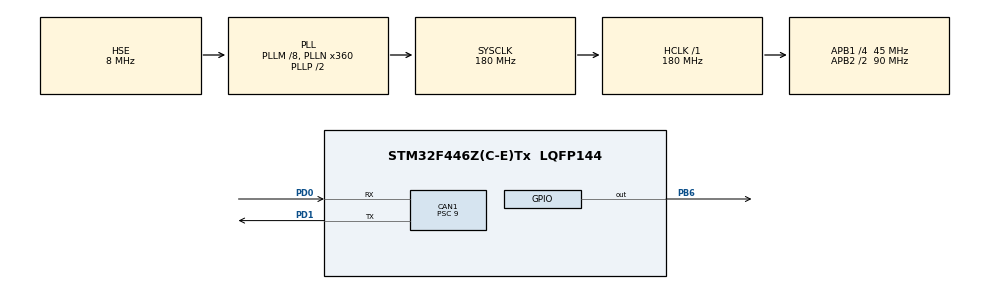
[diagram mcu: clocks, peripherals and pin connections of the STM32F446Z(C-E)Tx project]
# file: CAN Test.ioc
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CAN1.BS1=CAN_BS1_3TQ
CAN1.BS2=CAN_BS2_1TQ
CAN1.CalculateTimeBit=1000
CAN1.CalculateTimeQuantum=200.0
CAN1.Mode=CAN_MODE_NORMAL
CAN1.Prescaler=9
Mcu.Family=STM32F4
Mcu.Name=STM32F446Z(C-E)Tx
Mcu.Package=LQFP144
NVIC.PriorityGroup=NVIC_PRIORITYGROUP_4
PB6.Signal=GPIO_Output
PD0.Mode=Master
PD0.Signal=CAN1_RX
PD1.Mode=Master
PD1.Signal=CAN1_TX
PH0-OSC_IN.Mode=HSE-External-Oscillator
PH0-OSC_IN.Signal=RCC_OSC_IN
PH1-OSC_OUT.Mode=HSE-External-Oscillator
PH1-OSC_OUT.Signal=RCC_OSC_OUT
ProjectManager.HeapSize=0x200
ProjectManager.StackSize=0x400
ProjectManager.TargetToolchain=MDK-ARM V5
RCC.AHBFreq_Value=180000000
RCC.APB1CLKDivider=RCC_HCLK_DIV4
RCC.APB1Freq_Value=45000000
RCC.APB1TimFreq_Value=90000000
RCC.APB2CLKDivider=RCC_HCLK_DIV2
RCC.APB2Freq_Value=90000000
RCC.APB2TimFreq_Value=180000000
RCC.CortexFreq_Value=180000000
RCC.HCLKFreq_Value=180000000
RCC.HSE_VALUE=8000000
RCC.PLLM=8
RCC.PLLN=360
RCC.PLLSourceVirtual=RCC_PLLSOURCE_HSE
RCC.SYSCLKFreq_VALUE=180000000
RCC.SYSCLKSource=RCC_SYSCLKSOURCE_PLLCLK
RCC.USBFreq_Value=180000000
RCC.VCOOutputFreq_Value=360000000
board=CAN Test

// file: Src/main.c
/**
  ******************************************************************************
  * File Name          : main.c
  * Description        : Main program body
  ******************************************************************************
  ** This notice applies to any and all portions of this file
  * that are not between comment pairs USER CODE BEGIN and
  * USER CODE END. Other portions of this file, whether
  * inserted by the user or by software development tools
  * are owned by their respective copyright owners.
  *
  * COPYRIGHT(c) 2018 STMicroelectronics
  *
  * Redistribution and use in source and binary forms, with or without modification,
  * are permitted provided that the following conditions are met:
  *   1. Redistributions of source code must retain the above copyright notice,
  *      this list of conditions and the following disclaimer.
  *   2. Redistributions in binary form must reproduce the above copyright notice,
  *      this list of conditions and the following disclaimer in the documentation
  *      and/or other materials provided with the distribution.
  *   3. Neither the name of STMicroelectronics nor the names of its contributors
  *      may be used to endorse or promote products derived from this software
  *      without specific prior written permission.
  *
  * THIS SOFTWARE IS PROVIDED BY THE COPYRIGHT HOLDERS AND CONTRIBUTORS "AS IS"
  * AND ANY EXPRESS OR IMPLIED WARRANTIES, INCLUDING, BUT NOT LIMITED TO, THE
  * IMPLIED WARRANTIES OF MERCHANTABILITY AND FITNESS FOR A PARTICULAR PURPOSE ARE
  * DISCLAIMED. IN NO EVENT SHALL THE COPYRIGHT HOLDER OR CONTRIBUTORS BE LIABLE
  * FOR ANY DIRECT, INDIRECT, INCIDENTAL, SPECIAL, EXEMPLARY, OR CONSEQUENTIAL
  * DAMAGES (INCLUDING, BUT NOT LIMITED TO, PROCUREMENT OF SUBSTITUTE GOODS OR
  * SERVICES; LOSS OF USE, DATA, OR PROFITS; OR BUSINESS INTERRUPTION) HOWEVER
  * CAUSED AND ON ANY THEORY OF LIABILITY, WHETHER IN CONTRACT, STRICT LIABILITY,
  * OR TORT (INCLUDING NEGLIGENCE OR OTHERWISE) ARISING IN ANY WAY OUT OF THE USE
  * OF THIS SOFTWARE, EVEN IF ADVISED OF THE POSSIBILITY OF SUCH DAMAGE.
  *
  ******************************************************************************
  */

#include "main.h"
#include "stm32f4xx_hal.h"

CAN_HandleTypeDef hcan1;

/* USER CODE BEGIN PV */
/* Private variables ---------------------------------------------------------*/

/* USER CODE END PV */

void SystemClock_Config(void);
static void MX_GPIO_Init(void);
static void MX_CAN1_Init(void);

/* USER CODE BEGIN PFP */
/* Private function prototypes -----------------------------------------------*/

/* USER CODE END PFP */

int main(void)
{

  /* MCU Configuration----------------------------------------------------------*/

  /* Reset of all peripherals, Initializes the Flash interface and the Systick. */
  HAL_Init();

  /* Configure the system clock */
  SystemClock_Config();

  /* Initialize all configured peripherals */
  MX_GPIO_Init();
  MX_CAN1_Init();

  /* USER CODE BEGIN 2 */
	hcan1.pTxMsg->StdId = 0x110;
	hcan1.pTxMsg->RTR = CAN_RTR_DATA;
	hcan1.pTxMsg->IDE = CAN_ID_STD;
	hcan1.pTxMsg->DLC = 8;
  /* USER CODE END 2 */

  /* Infinite loop */
  while (1)
  {

  /* USER CODE BEGIN 3 */
		hcan1.pTxMsg->Data[0] = 1;
		hcan1.pTxMsg->Data[1] = 2;
		hcan1.pTxMsg->Data[2] = 3;
		hcan1.pTxMsg->Data[3] = 4;
		hcan1.pTxMsg->Data[4] = 0xCA;
		hcan1.pTxMsg->Data[5] = 0xFE;
		hcan1.pTxMsg->Data[6] = 0xCA;
		hcan1.pTxMsg->Data[7] = 0xFE;
		HAL_CAN_Transmit(&hcan1, 10);
		//HAL_Delay(1000);
		/*if(HAL_CAN_Receive(&hcan1,CAN_FIFO0, 10) == HAL_OK)
		{
			if(hcan1.pRxMsg->StdId  == 0x100)
			{
				if(hcan1.pRxMsg->IDE == CAN_ID_STD)
				{
					if(hcan1.pRxMsg->DLC == 2)
					{
						if(hcan1.pRxMsg->Data[0] == 0xCA)
						{
							if(hcan1.pRxMsg->Data[1] == 0xFE)
							{
								HAL_GPIO_TogglePin(GPIOB, GPIO_PIN_6);
								//HAL_Delay(100);
							}
						}
					}
				}
			}
		}*/
  }
  /* USER CODE END 3 */

}

/** System Clock Configuration
*/
void SystemClock_Config(void)
{

  RCC_OscInitTypeDef RCC_OscInitStruct;
  RCC_ClkInitTypeDef RCC_ClkInitStruct;

    /**Configure the main internal regulator output voltage
    */
  __HAL_RCC_PWR_CLK_ENABLE();

  __HAL_PWR_VOLTAGESCALING_CONFIG(PWR_REGULATOR_VOLTAGE_SCALE1);

    /**Initializes the CPU, AHB and APB busses clocks
    */
  RCC_OscInitStruct.OscillatorType = RCC_OSCILLATORTYPE_HSE;
  RCC_OscInitStruct.HSEState = RCC_HSE_ON;
  RCC_OscInitStruct.PLL.PLLState = RCC_PLL_ON;
  RCC_OscInitStruct.PLL.PLLSource = RCC_PLLSOURCE_HSE;
  RCC_OscInitStruct.PLL.PLLM = 8;
  RCC_OscInitStruct.PLL.PLLN = 360;
  RCC_OscInitStruct.PLL.PLLP = RCC_PLLP_DIV2;
  RCC_OscInitStruct.PLL.PLLQ = 2;
  RCC_OscInitStruct.PLL.PLLR = 2;
  if (HAL_RCC_OscConfig(&RCC_OscInitStruct) != HAL_OK)
  {
    _Error_Handler(__FILE__, __LINE__);
  }

    /**Activate the Over-Drive mode
    */
  if (HAL_PWREx_EnableOverDrive() != HAL_OK)
  {
    _Error_Handler(__FILE__, __LINE__);
  }

    /**Initializes the CPU, AHB and APB busses clocks
    */
  RCC_ClkInitStruct.ClockType = RCC_CLOCKTYPE_HCLK|RCC_CLOCKTYPE_SYSCLK
                              |RCC_CLOCKTYPE_PCLK1|RCC_CLOCKTYPE_PCLK2;
  RCC_ClkInitStruct.SYSCLKSource = RCC_SYSCLKSOURCE_PLLCLK;
  RCC_ClkInitStruct.AHBCLKDivider = RCC_SYSCLK_DIV1;
  RCC_ClkInitStruct.APB1CLKDivider = RCC_HCLK_DIV4;
  RCC_ClkInitStruct.APB2CLKDivider = RCC_HCLK_DIV2;

  if (HAL_RCC_ClockConfig(&RCC_ClkInitStruct, FLASH_LATENCY_5) != HAL_OK)
  {
    _Error_Handler(__FILE__, __LINE__);
  }

    /**Configure the Systick interrupt time
    */
  HAL_SYSTICK_Config(HAL_RCC_GetHCLKFreq()/1000);

    /**Configure the Systick
    */
  HAL_SYSTICK_CLKSourceConfig(SYSTICK_CLKSOURCE_HCLK);

  /* SysTick_IRQn interrupt configuration */
  HAL_NVIC_SetPriority(SysTick_IRQn, 0, 0);
}

/* CAN1 init function */
/* CAN1 init function */
static void MX_CAN1_Init(void)
{
	CAN_FilterConfTypeDef  sFilterConfig;
  static CanTxMsgTypeDef        TxMessage;
  static CanRxMsgTypeDef        RxMessage;

  hcan1.Instance = CAN1;
	hcan1.pTxMsg = &TxMessage;
  hcan1.pRxMsg = &RxMessage;

  hcan1.Init.Prescaler = 9;
  hcan1.Init.Mode = CAN_MODE_NORMAL;
  hcan1.Init.SJW = CAN_SJW_1TQ;
  hcan1.Init.BS1 = CAN_BS1_3TQ;
  hcan1.Init.BS2 = CAN_BS2_1TQ;
  hcan1.Init.TTCM = DISABLE;
  hcan1.Init.ABOM = DISABLE;
  hcan1.Init.AWUM = DISABLE;
  hcan1.Init.NART = DISABLE;
  hcan1.Init.RFLM = DISABLE;
  hcan1.Init.TXFP = DISABLE;
  if (HAL_CAN_Init(&hcan1) != HAL_OK)
  {
    _Error_Handler(__FILE__, __LINE__);
  }

	 /*##-2- Configure the CAN Filter ###########################################*/
  sFilterConfig.FilterNumber = 0;
  sFilterConfig.FilterMode = CAN_FILTERMODE_IDMASK;
  sFilterConfig.FilterScale = CAN_FILTERSCALE_32BIT;
  sFilterConfig.FilterIdHigh = 0x0000;
  sFilterConfig.FilterIdLow = 0x0000;
  sFilterConfig.FilterMaskIdHigh = 0x0000;
  sFilterConfig.FilterMaskIdLow = 0x0000;
  sFilterConfig.FilterFIFOAssignment = 0;
  sFilterConfig.FilterActivation = ENABLE;
  sFilterConfig.BankNumber = 14;

  if(HAL_CAN_ConfigFilter(&hcan1, &sFilterConfig) != HAL_OK)
  {
    /* Filter configuration Error */
    Error_Handler();
  }
}

/** Configure pins as
        * Analog
        * Input
        * Output
        * EVENT_OUT
        * EXTI
*/
static void MX_GPIO_Init(void)
{

  GPIO_InitTypeDef GPIO_InitStruct;

  /* GPIO Ports Clock Enable */
  __HAL_RCC_GPIOH_CLK_ENABLE();
  __HAL_RCC_GPIOD_CLK_ENABLE();
  __HAL_RCC_GPIOB_CLK_ENABLE();

  /*Configure GPIO pin Output Level */
  HAL_GPIO_WritePin(GPIOB, GPIO_PIN_6, GPIO_PIN_RESET);

  /*Configure GPIO pin : PB6 */
  GPIO_InitStruct.Pin = GPIO_PIN_6;
  GPIO_InitStruct.Mode = GPIO_MODE_OUTPUT_PP;
  GPIO_InitStruct.Pull = GPIO_NOPULL;
  GPIO_InitStruct.Speed = GPIO_SPEED_FREQ_LOW;
  HAL_GPIO_Init(GPIOB, &GPIO_InitStruct);

}

void _Error_Handler(char * file, int line)
{
  /* USER CODE BEGIN Error_Handler_Debug */
  /* User can add his own implementation to report the HAL error return state */
  while(1)
  {
		HAL_GPIO_WritePin(GPIOB,GPIO_PIN_6,GPIO_PIN_SET);
  }
  /* USER CODE END Error_Handler_Debug */
}

/************************ (C) COPYRIGHT STMicroelectronics *****END OF FILE****/
